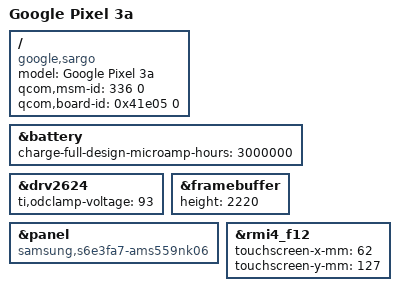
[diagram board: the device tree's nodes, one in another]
// SPDX-License-Identifier: GPL-2.0-only
/*
 * Pixel 3a (sargo, board S4) personality overlay for the b4s4 base dtb.
 *
 * Root properties are read by ABL to match this overlay against the
 * board's SMEM-reported IDs (qcom,msm-id + qcom,board-id), then the
 * fragments below are applied onto the base dtb. Mirrors stock dtbo.
 */

/dts-v1/;
/plugin/;

/ {
	model = "Google Pixel 3a";
	compatible = "google,sargo", "google,b4s4-sdm670", "qcom,sdm670";
	qcom,msm-id = <336 0>;
	qcom,board-id = <0x41e05 0>;	/* S4 PVT */
};

&battery {
	charge-full-design-microamp-hours = <3000000>;
};

&drv2624 {
	ti,odclamp-voltage = <93>; /* 1.8 Vrms */
};

&framebuffer {
	height = <2220>;
};

&panel {
	compatible = "samsung,s6e3fa7-ams559nk06";
};

&rmi4_f12 {
	touchscreen-x-mm = <62>;
	touchscreen-y-mm = <127>;
};
